# iqn_dio2 register map
Vendor: Texas Instruments
Registers are 32-bit, read-only, no defined reset value unless marked. A register's access mark holds for its fields unless they carry their own. Offsets are as the file gives them; [hi:lo] are bit positions; lines under a group give offsets from that group.

## IQN_DIO2 (part 2 of 2)
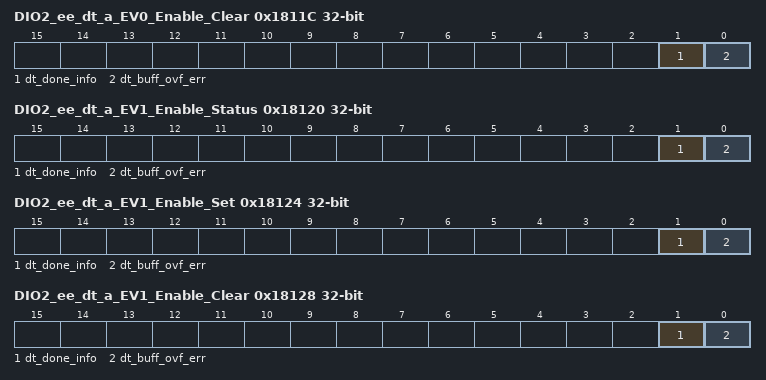
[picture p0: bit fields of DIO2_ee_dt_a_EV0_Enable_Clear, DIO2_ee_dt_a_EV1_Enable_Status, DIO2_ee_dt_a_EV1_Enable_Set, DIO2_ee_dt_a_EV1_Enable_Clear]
0x1811C DIO2_ee_dt_a_EV0_Enable_Clear wo — (1 of 1, stride 0)
  [1] dt_done_info — Clears the corresponding bit in the enable register when set. Write only, self-clears.
  [0] dt_buff_ovf_err — Clears the corresponding bit in the enable register when set. Write only, self-clears.
0x18120 DIO2_ee_dt_a_EV1_Enable_Status — (1 of 1, stride 0)
  [1] dt_done_info — When set allows the corresponding bit in the raw_status register to generate the intr1_sts interrupt. Read only.
  [0] dt_buff_ovf_err — When set allows the corresponding bit in the raw_status register to generate the intr1_sts interrupt. Read only.
0x18124 DIO2_ee_dt_a_EV1_Enable_Set wo — (1 of 1, stride 0)
  [1] dt_done_info — Sets the corresponding bit in the intr1_status register when set. Write only, self-clears.
  [0] dt_buff_ovf_err — Sets the corresponding bit in the intr1_status register when set. Write only, self-clears.
0x18128 DIO2_ee_dt_a_EV1_Enable_Clear wo — (1 of 1, stride 0)
  [1] dt_done_info — Clears the corresponding bit in the intr1_status register when set. Write only, self-clears.
  [0] dt_buff_ovf_err — Clears the corresponding bit in the intr1_status register when set. Write only, self-clears.
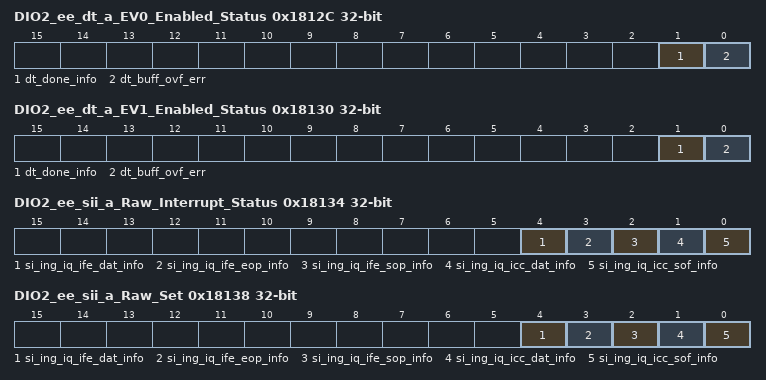
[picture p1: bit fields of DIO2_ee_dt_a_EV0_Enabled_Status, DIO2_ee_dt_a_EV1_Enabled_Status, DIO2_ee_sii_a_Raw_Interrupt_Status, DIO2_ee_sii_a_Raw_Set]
0x1812C DIO2_ee_dt_a_EV0_Enabled_Status — (1 of 1, stride 0)
  [1] dt_done_info — AND-ed raw_status bits with the corresponding bit in the enable_status register. Read only.
  [0] dt_buff_ovf_err — AND-ed raw_status bits with the corresponding bit in the enable_status register. Read only.
0x18130 DIO2_ee_dt_a_EV1_Enabled_Status — (1 of 1, stride 0)
  [1] dt_done_info — AND-ed raw_status bits with the corresponding bit in the intr1_status register. Read only.
  [0] dt_buff_ovf_err — AND-ed raw_status bits with the corresponding bit in the intr1_status register. Read only.
0x18134 DIO2_ee_sii_a_Raw_Interrupt_Status — (1 of 1, stride 0)
  [4] si_ing_iq_ife_dat_info — DIO SI Ingress IQ IFE transmitted valid data phase
  [3] si_ing_iq_ife_eop_info — DIO SI Ingress IQ IFE transmitted EOP
  [2] si_ing_iq_ife_sop_info — DIO SI Ingress IQ IFE transmitted SOP
  [1] si_ing_iq_icc_dat_info — DIO SI Ingress IQ ICC data transfer received
  [0] si_ing_iq_icc_sof_info — DIO SI Ingress IQ ICC Start of Frame received
0x18138 DIO2_ee_sii_a_Raw_Set wo — (1 of 1, stride 0)
  [4] si_ing_iq_ife_dat_info — Sets the corresponding bit in the raw_status register when set. Write only, self-clears.
  [3] si_ing_iq_ife_eop_info — Sets the corresponding bit in the raw_status register when set. Write only, self-clears.
  [2] si_ing_iq_ife_sop_info — Sets the corresponding bit in the raw_status register when set. Write only, self-clears.
  [1] si_ing_iq_icc_dat_info — Sets the corresponding bit in the raw_status register when set. Write only, self-clears.
  [0] si_ing_iq_icc_sof_info — Sets the corresponding bit in the raw_status register when set. Write only, self-clears.
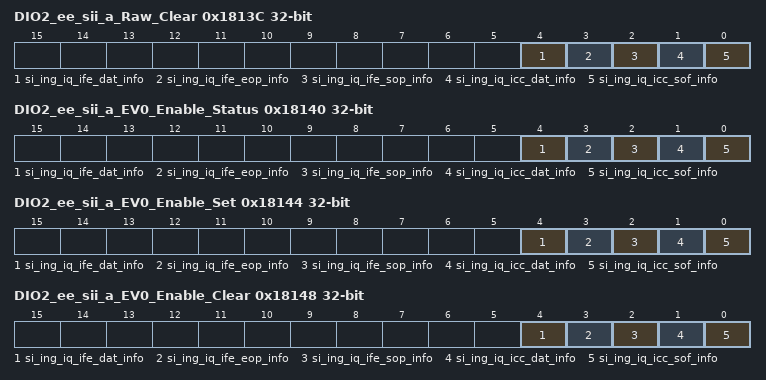
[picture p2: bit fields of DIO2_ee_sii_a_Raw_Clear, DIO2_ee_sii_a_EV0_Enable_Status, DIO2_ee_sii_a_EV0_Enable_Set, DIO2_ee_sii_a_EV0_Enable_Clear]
0x1813C DIO2_ee_sii_a_Raw_Clear wo — (1 of 1, stride 0)
  [4] si_ing_iq_ife_dat_info — Clears the corresponding bit in the raw_status register when set. Write only, self-clears.
  [3] si_ing_iq_ife_eop_info — Clears the corresponding bit in the raw_status register when set. Write only, self-clears.
  [2] si_ing_iq_ife_sop_info — Clears the corresponding bit in the raw_status register when set. Write only, self-clears.
  [1] si_ing_iq_icc_dat_info — Clears the corresponding bit in the raw_status register when set. Write only, self-clears.
  [0] si_ing_iq_icc_sof_info — Clears the corresponding bit in the raw_status register when set. Write only, self-clears.
0x18140 DIO2_ee_sii_a_EV0_Enable_Status — (1 of 1, stride 0)
  [4] si_ing_iq_ife_dat_info — When set allows the corresponding bit in the raw_status register to generate the intr_sts interrupt. Read only.
  [3] si_ing_iq_ife_eop_info — When set allows the corresponding bit in the raw_status register to generate the intr_sts interrupt. Read only.
  [2] si_ing_iq_ife_sop_info — When set allows the corresponding bit in the raw_status register to generate the intr_sts interrupt. Read only.
  [1] si_ing_iq_icc_dat_info — When set allows the corresponding bit in the raw_status register to generate the intr_sts interrupt. Read only.
  [0] si_ing_iq_icc_sof_info — When set allows the corresponding bit in the raw_status register to generate the intr_sts interrupt. Read only.
0x18144 DIO2_ee_sii_a_EV0_Enable_Set wo — (1 of 1, stride 0)
  [4] si_ing_iq_ife_dat_info — Sets the corresponding bit in the enable register when set. Write only, self-clears.
  [3] si_ing_iq_ife_eop_info — Sets the corresponding bit in the enable register when set. Write only, self-clears.
  [2] si_ing_iq_ife_sop_info — Sets the corresponding bit in the enable register when set. Write only, self-clears.
  [1] si_ing_iq_icc_dat_info — Sets the corresponding bit in the enable register when set. Write only, self-clears.
  [0] si_ing_iq_icc_sof_info — Sets the corresponding bit in the enable register when set. Write only, self-clears.
0x18148 DIO2_ee_sii_a_EV0_Enable_Clear wo — (1 of 1, stride 0)
  [4] si_ing_iq_ife_dat_info — Clears the corresponding bit in the enable register when set. Write only, self-clears.
  [3] si_ing_iq_ife_eop_info — Clears the corresponding bit in the enable register when set. Write only, self-clears.
  [2] si_ing_iq_ife_sop_info — Clears the corresponding bit in the enable register when set. Write only, self-clears.
  [1] si_ing_iq_icc_dat_info — Clears the corresponding bit in the enable register when set. Write only, self-clears.
  [0] si_ing_iq_icc_sof_info — Clears the corresponding bit in the enable register when set. Write only, self-clears.
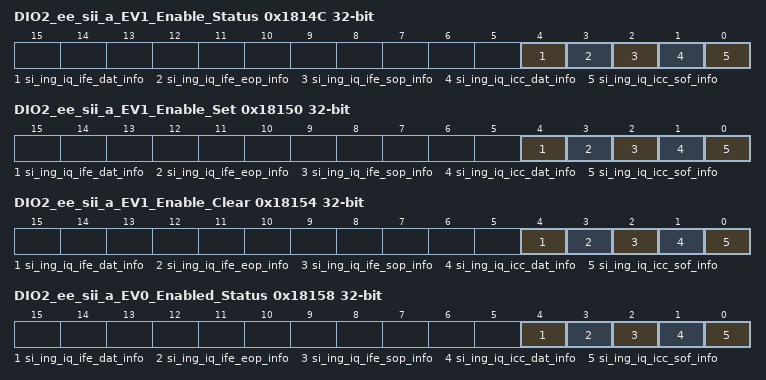
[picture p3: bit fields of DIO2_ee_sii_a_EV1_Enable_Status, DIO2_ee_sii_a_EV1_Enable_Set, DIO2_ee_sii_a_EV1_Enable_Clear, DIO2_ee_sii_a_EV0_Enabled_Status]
0x1814C DIO2_ee_sii_a_EV1_Enable_Status — (1 of 1, stride 0)
  [4] si_ing_iq_ife_dat_info — When set allows the corresponding bit in the raw_status register to generate the intr1_sts interrupt. Read only.
  [3] si_ing_iq_ife_eop_info — When set allows the corresponding bit in the raw_status register to generate the intr1_sts interrupt. Read only.
  [2] si_ing_iq_ife_sop_info — When set allows the corresponding bit in the raw_status register to generate the intr1_sts interrupt. Read only.
  [1] si_ing_iq_icc_dat_info — When set allows the corresponding bit in the raw_status register to generate the intr1_sts interrupt. Read only.
  [0] si_ing_iq_icc_sof_info — When set allows the corresponding bit in the raw_status register to generate the intr1_sts interrupt. Read only.
0x18150 DIO2_ee_sii_a_EV1_Enable_Set wo — (1 of 1, stride 0)
  [4] si_ing_iq_ife_dat_info — Sets the corresponding bit in the intr1_status register when set. Write only, self-clears.
  [3] si_ing_iq_ife_eop_info — Sets the corresponding bit in the intr1_status register when set. Write only, self-clears.
  [2] si_ing_iq_ife_sop_info — Sets the corresponding bit in the intr1_status register when set. Write only, self-clears.
  [1] si_ing_iq_icc_dat_info — Sets the corresponding bit in the intr1_status register when set. Write only, self-clears.
  [0] si_ing_iq_icc_sof_info — Sets the corresponding bit in the intr1_status register when set. Write only, self-clears.
0x18154 DIO2_ee_sii_a_EV1_Enable_Clear wo — (1 of 1, stride 0)
  [4] si_ing_iq_ife_dat_info — Clears the corresponding bit in the intr1_status register when set. Write only, self-clears.
  [3] si_ing_iq_ife_eop_info — Clears the corresponding bit in the intr1_status register when set. Write only, self-clears.
  [2] si_ing_iq_ife_sop_info — Clears the corresponding bit in the intr1_status register when set. Write only, self-clears.
  [1] si_ing_iq_icc_dat_info — Clears the corresponding bit in the intr1_status register when set. Write only, self-clears.
  [0] si_ing_iq_icc_sof_info — Clears the corresponding bit in the intr1_status register when set. Write only, self-clears.
0x18158 DIO2_ee_sii_a_EV0_Enabled_Status — (1 of 1, stride 0)
  [4] si_ing_iq_ife_dat_info — AND-ed raw_status bits with the corresponding bit in the enable_status register. Read only.
  [3] si_ing_iq_ife_eop_info — AND-ed raw_status bits with the corresponding bit in the enable_status register. Read only.
  [2] si_ing_iq_ife_sop_info — AND-ed raw_status bits with the corresponding bit in the enable_status register. Read only.
  [1] si_ing_iq_icc_dat_info — AND-ed raw_status bits with the corresponding bit in the enable_status register. Read only.
  [0] si_ing_iq_icc_sof_info — AND-ed raw_status bits with the corresponding bit in the enable_status register. Read only.
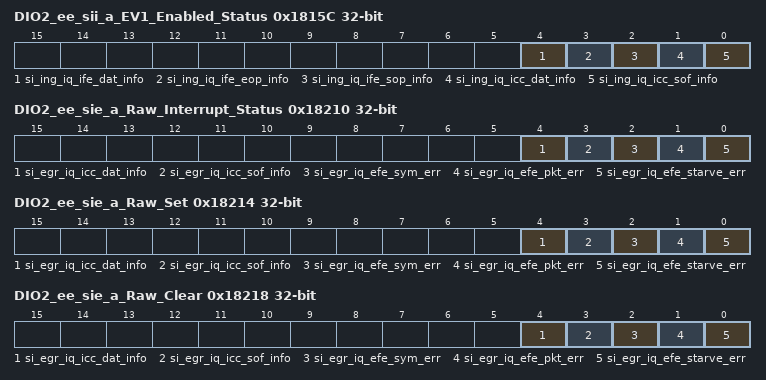
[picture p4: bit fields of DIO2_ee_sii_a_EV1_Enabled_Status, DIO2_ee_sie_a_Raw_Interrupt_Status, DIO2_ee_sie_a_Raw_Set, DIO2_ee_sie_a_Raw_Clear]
0x1815C DIO2_ee_sii_a_EV1_Enabled_Status — (1 of 1, stride 0)
  [4] si_ing_iq_ife_dat_info — AND-ed raw_status bits with the corresponding bit in the intr1_status register. Read only.
  [3] si_ing_iq_ife_eop_info — AND-ed raw_status bits with the corresponding bit in the intr1_status register. Read only.
  [2] si_ing_iq_ife_sop_info — AND-ed raw_status bits with the corresponding bit in the intr1_status register. Read only.
  [1] si_ing_iq_icc_dat_info — AND-ed raw_status bits with the corresponding bit in the intr1_status register. Read only.
  [0] si_ing_iq_icc_sof_info — AND-ed raw_status bits with the corresponding bit in the intr1_status register. Read only.
0x18160 DIO2_ee_sii_c_Raw_Interrupt_Status — (1 of 1, stride 0)
  [15:0] si_ing_iq_sof_err — DIO SI Ingress IQ per channel Start of Frame alignment error
0x18164 DIO2_ee_sii_c_Raw_Set wo — (1 of 1, stride 0)
  [15:0] si_ing_iq_sof_err — Sets the corresponding bit in the raw_status register when set. Write only, self-clears.
0x18168 DIO2_ee_sii_c_Raw_Clear wo — (1 of 1, stride 0)
  [15:0] si_ing_iq_sof_err — Clears the corresponding bit in the raw_status register when set. Write only, self-clears.
0x1816C DIO2_ee_sii_c_EV0_Enable_Status — (1 of 1, stride 0)
  [15:0] si_ing_iq_sof_err — When set allows the corresponding bit in the raw_status register to generate the intr_sts interrupt. Read only.
0x18170 DIO2_ee_sii_c_EV0_Enable_Set wo — (1 of 1, stride 0)
  [15:0] si_ing_iq_sof_err — Sets the corresponding bit in the enable register when set. Write only, self-clears.
0x18174 DIO2_ee_sii_c_EV0_Enable_Clear wo — (1 of 1, stride 0)
  [15:0] si_ing_iq_sof_err — Clears the corresponding bit in the enable register when set. Write only, self-clears.
0x18178 DIO2_ee_sii_c_EV1_Enable_Status — (1 of 1, stride 0)
  [15:0] si_ing_iq_sof_err — When set allows the corresponding bit in the raw_status register to generate the intr1_sts interrupt. Read only.
0x1817C DIO2_ee_sii_c_EV1_Enable_Set wo — (1 of 1, stride 0)
  [15:0] si_ing_iq_sof_err — Sets the corresponding bit in the intr1_status register when set. Write only, self-clears.
0x18180 DIO2_ee_sii_c_EV1_Enable_Clear wo — (1 of 1, stride 0)
  [15:0] si_ing_iq_sof_err — Clears the corresponding bit in the intr1_status register when set. Write only, self-clears.
0x18184 DIO2_ee_sii_c_EV0_Enabled_Status — (1 of 1, stride 0)
  [15:0] si_ing_iq_sof_err — AND-ed raw_status bits with the corresponding bit in the enable_status register. Read only.
0x18188 DIO2_ee_sii_c_EV1_Enabled_Status — (1 of 1, stride 0)
  [15:0] si_ing_iq_sof_err — AND-ed raw_status bits with the corresponding bit in the intr1_status register. Read only.
0x18210 DIO2_ee_sie_a_Raw_Interrupt_Status — (1 of 1, stride 0)
  [4] si_egr_iq_icc_dat_info — DIO SI Egress IQ transmitted data to ICC
  [3] si_egr_iq_icc_sof_info — DIO SI Egress IQ transmitted Start of Frame to ICC
  [2] si_egr_iq_efe_sym_err — DIO SI Egress IQ EFE symbol number error. (Packet boundary errors due to a missing, early, or late SOP disable the reporting of any symbol errors since the symbol number is only valid for SOPs)
  [1] si_egr_iq_efe_pkt_err — DIO SI Egress IQ EFE packet boundary error
  [0] si_egr_iq_efe_starve_err — DIO SI Egress IQ EFE data starvation error
0x18214 DIO2_ee_sie_a_Raw_Set wo — (1 of 1, stride 0)
  [4] si_egr_iq_icc_dat_info — Sets the corresponding bit in the raw_status register when set. Write only, self-clears.
  [3] si_egr_iq_icc_sof_info — Sets the corresponding bit in the raw_status register when set. Write only, self-clears.
  [2] si_egr_iq_efe_sym_err — Sets the corresponding bit in the raw_status register when set. Write only, self-clears.
  [1] si_egr_iq_efe_pkt_err — Sets the corresponding bit in the raw_status register when set. Write only, self-clears.
  [0] si_egr_iq_efe_starve_err — Sets the corresponding bit in the raw_status register when set. Write only, self-clears.
0x18218 DIO2_ee_sie_a_Raw_Clear wo — (1 of 1, stride 0)
  [4] si_egr_iq_icc_dat_info — Clears the corresponding bit in the raw_status register when set. Write only, self-clears.
  [3] si_egr_iq_icc_sof_info — Clears the corresponding bit in the raw_status register when set. Write only, self-clears.
  [2] si_egr_iq_efe_sym_err — Clears the corresponding bit in the raw_status register when set. Write only, self-clears.
  [1] si_egr_iq_efe_pkt_err — Clears the corresponding bit in the raw_status register when set. Write only, self-clears.
  [0] si_egr_iq_efe_starve_err — Clears the corresponding bit in the raw_status register when set. Write only, self-clears.
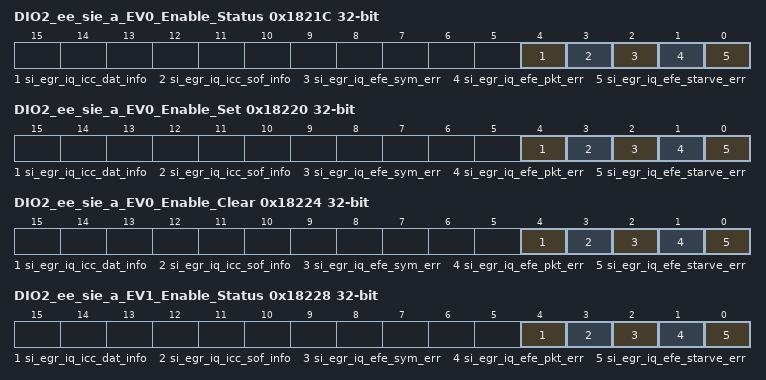
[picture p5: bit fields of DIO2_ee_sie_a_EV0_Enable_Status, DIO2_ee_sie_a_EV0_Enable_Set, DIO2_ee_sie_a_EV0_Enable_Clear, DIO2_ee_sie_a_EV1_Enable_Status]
0x1821C DIO2_ee_sie_a_EV0_Enable_Status — (1 of 1, stride 0)
  [4] si_egr_iq_icc_dat_info — When set allows the corresponding bit in the raw_status register to generate the intr_sts interrupt. Read only.
  [3] si_egr_iq_icc_sof_info — When set allows the corresponding bit in the raw_status register to generate the intr_sts interrupt. Read only.
  [2] si_egr_iq_efe_sym_err — When set allows the corresponding bit in the raw_status register to generate the intr_sts interrupt. Read only.
  [1] si_egr_iq_efe_pkt_err — When set allows the corresponding bit in the raw_status register to generate the intr_sts interrupt. Read only.
  [0] si_egr_iq_efe_starve_err — When set allows the corresponding bit in the raw_status register to generate the intr_sts interrupt. Read only.
0x18220 DIO2_ee_sie_a_EV0_Enable_Set wo — (1 of 1, stride 0)
  [4] si_egr_iq_icc_dat_info — Sets the corresponding bit in the enable register when set. Write only, self-clears.
  [3] si_egr_iq_icc_sof_info — Sets the corresponding bit in the enable register when set. Write only, self-clears.
  [2] si_egr_iq_efe_sym_err — Sets the corresponding bit in the enable register when set. Write only, self-clears.
  [1] si_egr_iq_efe_pkt_err — Sets the corresponding bit in the enable register when set. Write only, self-clears.
  [0] si_egr_iq_efe_starve_err — Sets the corresponding bit in the enable register when set. Write only, self-clears.
0x18224 DIO2_ee_sie_a_EV0_Enable_Clear wo — (1 of 1, stride 0)
  [4] si_egr_iq_icc_dat_info — Clears the corresponding bit in the enable register when set. Write only, self-clears.
  [3] si_egr_iq_icc_sof_info — Clears the corresponding bit in the enable register when set. Write only, self-clears.
  [2] si_egr_iq_efe_sym_err — Clears the corresponding bit in the enable register when set. Write only, self-clears.
  [1] si_egr_iq_efe_pkt_err — Clears the corresponding bit in the enable register when set. Write only, self-clears.
  [0] si_egr_iq_efe_starve_err — Clears the corresponding bit in the enable register when set. Write only, self-clears.
0x18228 DIO2_ee_sie_a_EV1_Enable_Status — (1 of 1, stride 0)
  [4] si_egr_iq_icc_dat_info — When set allows the corresponding bit in the raw_status register to generate the intr1_sts interrupt. Read only.
  [3] si_egr_iq_icc_sof_info — When set allows the corresponding bit in the raw_status register to generate the intr1_sts interrupt. Read only.
  [2] si_egr_iq_efe_sym_err — When set allows the corresponding bit in the raw_status register to generate the intr1_sts interrupt. Read only.
  [1] si_egr_iq_efe_pkt_err — When set allows the corresponding bit in the raw_status register to generate the intr1_sts interrupt. Read only.
  [0] si_egr_iq_efe_starve_err — When set allows the corresponding bit in the raw_status register to generate the intr1_sts interrupt. Read only.
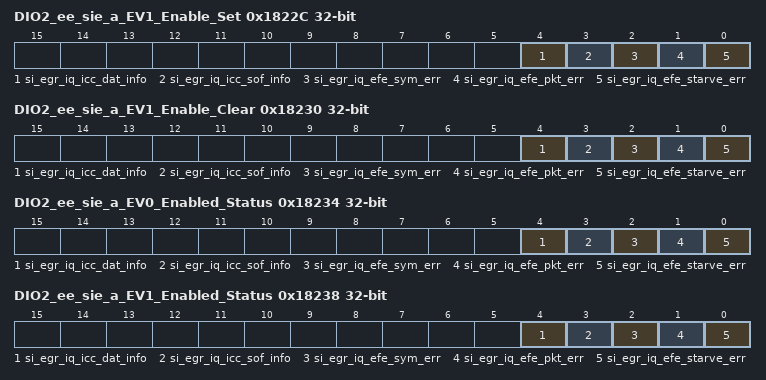
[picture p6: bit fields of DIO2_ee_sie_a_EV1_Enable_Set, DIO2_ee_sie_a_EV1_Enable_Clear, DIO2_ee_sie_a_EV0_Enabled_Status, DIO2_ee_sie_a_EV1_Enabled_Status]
0x1822C DIO2_ee_sie_a_EV1_Enable_Set wo — (1 of 1, stride 0)
  [4] si_egr_iq_icc_dat_info — Sets the corresponding bit in the intr1_status register when set. Write only, self-clears.
  [3] si_egr_iq_icc_sof_info — Sets the corresponding bit in the intr1_status register when set. Write only, self-clears.
  [2] si_egr_iq_efe_sym_err — Sets the corresponding bit in the intr1_status register when set. Write only, self-clears.
  [1] si_egr_iq_efe_pkt_err — Sets the corresponding bit in the intr1_status register when set. Write only, self-clears.
  [0] si_egr_iq_efe_starve_err — Sets the corresponding bit in the intr1_status register when set. Write only, self-clears.
0x18230 DIO2_ee_sie_a_EV1_Enable_Clear wo — (1 of 1, stride 0)
  [4] si_egr_iq_icc_dat_info — Clears the corresponding bit in the intr1_status register when set. Write only, self-clears.
  [3] si_egr_iq_icc_sof_info — Clears the corresponding bit in the intr1_status register when set. Write only, self-clears.
  [2] si_egr_iq_efe_sym_err — Clears the corresponding bit in the intr1_status register when set. Write only, self-clears.
  [1] si_egr_iq_efe_pkt_err — Clears the corresponding bit in the intr1_status register when set. Write only, self-clears.
  [0] si_egr_iq_efe_starve_err — Clears the corresponding bit in the intr1_status register when set. Write only, self-clears.
0x18234 DIO2_ee_sie_a_EV0_Enabled_Status — (1 of 1, stride 0)
  [4] si_egr_iq_icc_dat_info — AND-ed raw_status bits with the corresponding bit in the enable_status register. Read only.
  [3] si_egr_iq_icc_sof_info — AND-ed raw_status bits with the corresponding bit in the enable_status register. Read only.
  [2] si_egr_iq_efe_sym_err — AND-ed raw_status bits with the corresponding bit in the enable_status register. Read only.
  [1] si_egr_iq_efe_pkt_err — AND-ed raw_status bits with the corresponding bit in the enable_status register. Read only.
  [0] si_egr_iq_efe_starve_err — AND-ed raw_status bits with the corresponding bit in the enable_status register. Read only.
0x18238 DIO2_ee_sie_a_EV1_Enabled_Status — (1 of 1, stride 0)
  [4] si_egr_iq_icc_dat_info — AND-ed raw_status bits with the corresponding bit in the intr1_status register. Read only.
  [3] si_egr_iq_icc_sof_info — AND-ed raw_status bits with the corresponding bit in the intr1_status register. Read only.
  [2] si_egr_iq_efe_sym_err — AND-ed raw_status bits with the corresponding bit in the intr1_status register. Read only.
  [1] si_egr_iq_efe_pkt_err — AND-ed raw_status bits with the corresponding bit in the intr1_status register. Read only.
  [0] si_egr_iq_efe_starve_err — AND-ed raw_status bits with the corresponding bit in the intr1_status register. Read only.
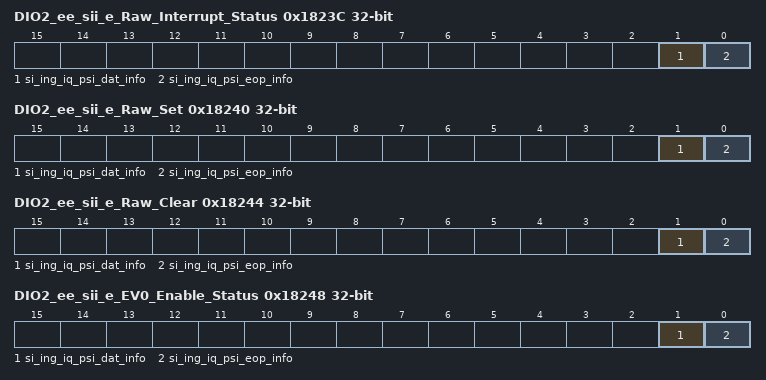
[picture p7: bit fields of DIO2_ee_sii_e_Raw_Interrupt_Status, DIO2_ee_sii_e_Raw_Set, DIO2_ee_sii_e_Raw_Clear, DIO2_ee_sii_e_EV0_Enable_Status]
0x1823C DIO2_ee_sii_e_Raw_Interrupt_Status — (1 of 1, stride 0)
  [1] si_ing_iq_psi_dat_info — DIO SI Ingress IQ data transmitted to PSI
  [0] si_ing_iq_psi_eop_info — DIO SI Ingress IQ EOP transmitted to PSI
0x18240 DIO2_ee_sii_e_Raw_Set wo — (1 of 1, stride 0)
  [1] si_ing_iq_psi_dat_info — Sets the corresponding bit in the raw_status register when set. Write only, self-clears.
  [0] si_ing_iq_psi_eop_info — Sets the corresponding bit in the raw_status register when set. Write only, self-clears.
0x18244 DIO2_ee_sii_e_Raw_Clear wo — (1 of 1, stride 0)
  [1] si_ing_iq_psi_dat_info — Clears the corresponding bit in the raw_status register when set. Write only, self-clears.
  [0] si_ing_iq_psi_eop_info — Clears the corresponding bit in the raw_status register when set. Write only, self-clears.
0x18248 DIO2_ee_sii_e_EV0_Enable_Status — (1 of 1, stride 0)
  [1] si_ing_iq_psi_dat_info — When set allows the corresponding bit in the raw_status register to generate the intr_sts interrupt. Read only.
  [0] si_ing_iq_psi_eop_info — When set allows the corresponding bit in the raw_status register to generate the intr_sts interrupt. Read only.
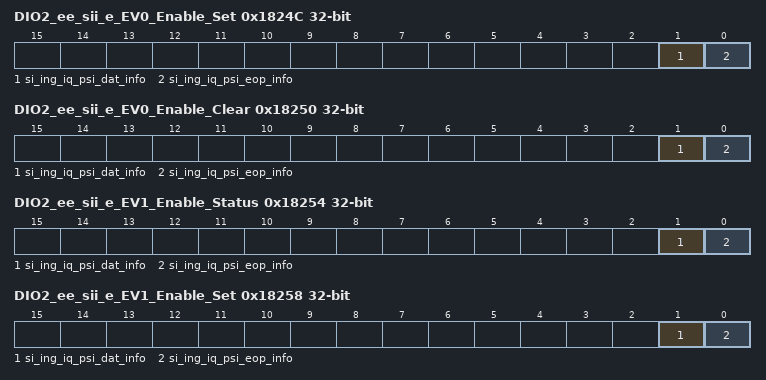
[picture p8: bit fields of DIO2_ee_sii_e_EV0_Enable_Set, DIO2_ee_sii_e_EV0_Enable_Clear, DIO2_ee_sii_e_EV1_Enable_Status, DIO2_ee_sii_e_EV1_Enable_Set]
0x1824C DIO2_ee_sii_e_EV0_Enable_Set wo — (1 of 1, stride 0)
  [1] si_ing_iq_psi_dat_info — Sets the corresponding bit in the enable register when set. Write only, self-clears.
  [0] si_ing_iq_psi_eop_info — Sets the corresponding bit in the enable register when set. Write only, self-clears.
0x18250 DIO2_ee_sii_e_EV0_Enable_Clear wo — (1 of 1, stride 0)
  [1] si_ing_iq_psi_dat_info — Clears the corresponding bit in the enable register when set. Write only, self-clears.
  [0] si_ing_iq_psi_eop_info — Clears the corresponding bit in the enable register when set. Write only, self-clears.
0x18254 DIO2_ee_sii_e_EV1_Enable_Status — (1 of 1, stride 0)
  [1] si_ing_iq_psi_dat_info — When set allows the corresponding bit in the raw_status register to generate the intr1_sts interrupt. Read only.
  [0] si_ing_iq_psi_eop_info — When set allows the corresponding bit in the raw_status register to generate the intr1_sts interrupt. Read only.
0x18258 DIO2_ee_sii_e_EV1_Enable_Set wo — (1 of 1, stride 0)
  [1] si_ing_iq_psi_dat_info — Sets the corresponding bit in the intr1_status register when set. Write only, self-clears.
  [0] si_ing_iq_psi_eop_info — Sets the corresponding bit in the intr1_status register when set. Write only, self-clears.
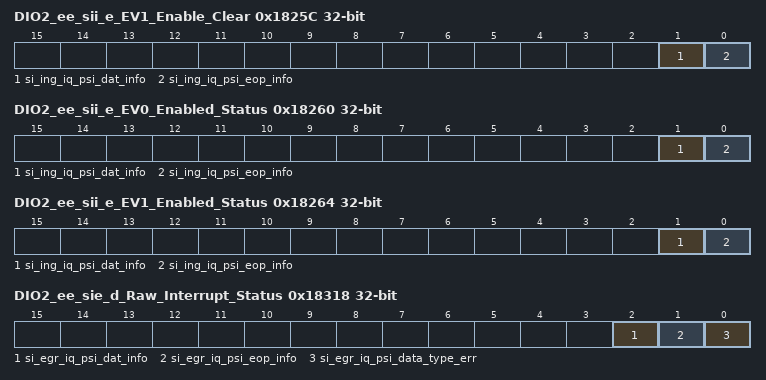
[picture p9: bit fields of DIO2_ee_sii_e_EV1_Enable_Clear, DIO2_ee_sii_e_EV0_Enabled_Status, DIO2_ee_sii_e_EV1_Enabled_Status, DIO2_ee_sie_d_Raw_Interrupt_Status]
0x1825C DIO2_ee_sii_e_EV1_Enable_Clear wo — (1 of 1, stride 0)
  [1] si_ing_iq_psi_dat_info — Clears the corresponding bit in the intr1_status register when set. Write only, self-clears.
  [0] si_ing_iq_psi_eop_info — Clears the corresponding bit in the intr1_status register when set. Write only, self-clears.
0x18260 DIO2_ee_sii_e_EV0_Enabled_Status — (1 of 1, stride 0)
  [1] si_ing_iq_psi_dat_info — AND-ed raw_status bits with the corresponding bit in the enable_status register. Read only.
  [0] si_ing_iq_psi_eop_info — AND-ed raw_status bits with the corresponding bit in the enable_status register. Read only.
0x18264 DIO2_ee_sii_e_EV1_Enabled_Status — (1 of 1, stride 0)
  [1] si_ing_iq_psi_dat_info — AND-ed raw_status bits with the corresponding bit in the intr1_status register. Read only.
  [0] si_ing_iq_psi_eop_info — AND-ed raw_status bits with the corresponding bit in the intr1_status register. Read only.
0x18268 DIO2_ee_sii_g_Raw_Interrupt_Status — (1 of 1, stride 0)
  [15:0] si_ing_iq_psi_sop_info — DIO SI Ingress IQ SOP transmitted to PSI
0x1826C DIO2_ee_sii_g_Raw_Set wo — (1 of 1, stride 0)
  [15:0] si_ing_iq_psi_sop_info — Sets the corresponding bit in the raw_status register when set. Write only, self-clears.
0x18270 DIO2_ee_sii_g_Raw_Clear wo — (1 of 1, stride 0)
  [15:0] si_ing_iq_psi_sop_info — Clears the corresponding bit in the raw_status register when set. Write only, self-clears.
0x18274 DIO2_ee_sii_g_EV0_Enable_Status — (1 of 1, stride 0)
  [15:0] si_ing_iq_psi_sop_info — When set allows the corresponding bit in the raw_status register to generate the intr_sts interrupt. Read only.
0x18278 DIO2_ee_sii_g_EV0_Enable_Set wo — (1 of 1, stride 0)
  [15:0] si_ing_iq_psi_sop_info — Sets the corresponding bit in the enable register when set. Write only, self-clears.
0x1827C DIO2_ee_sii_g_EV0_Enable_Clear wo — (1 of 1, stride 0)
  [15:0] si_ing_iq_psi_sop_info — Clears the corresponding bit in the enable register when set. Write only, self-clears.
0x18280 DIO2_ee_sii_g_EV1_Enable_Status — (1 of 1, stride 0)
  [15:0] si_ing_iq_psi_sop_info — When set allows the corresponding bit in the raw_status register to generate the intr1_sts interrupt. Read only.
0x18284 DIO2_ee_sii_g_EV1_Enable_Set wo — (1 of 1, stride 0)
  [15:0] si_ing_iq_psi_sop_info — Sets the corresponding bit in the intr1_status register when set. Write only, self-clears.
0x18288 DIO2_ee_sii_g_EV1_Enable_Clear wo — (1 of 1, stride 0)
  [15:0] si_ing_iq_psi_sop_info — Clears the corresponding bit in the intr1_status register when set. Write only, self-clears.
0x1828C DIO2_ee_sii_g_EV0_Enabled_Status — (1 of 1, stride 0)
  [15:0] si_ing_iq_psi_sop_info — AND-ed raw_status bits with the corresponding bit in the enable_status register. Read only.
0x18290 DIO2_ee_sii_g_EV1_Enabled_Status — (1 of 1, stride 0)
  [15:0] si_ing_iq_psi_sop_info — AND-ed raw_status bits with the corresponding bit in the intr1_status register. Read only.
0x18318 DIO2_ee_sie_d_Raw_Interrupt_Status — (1 of 1, stride 0)
  [2] si_egr_iq_psi_dat_info — DIO SI Egress IQ valid data received from PSI
  [1] si_egr_iq_psi_eop_info — DIO SI Egress IQ EOP received from PSI
  [0] si_egr_iq_psi_data_type_err — DIO SI Egress IQ PSI data type error
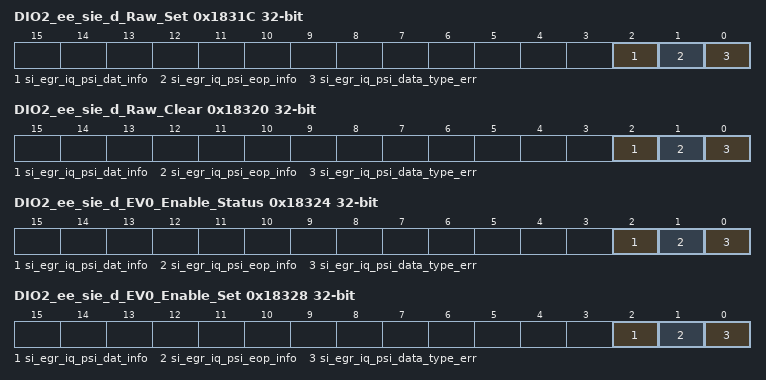
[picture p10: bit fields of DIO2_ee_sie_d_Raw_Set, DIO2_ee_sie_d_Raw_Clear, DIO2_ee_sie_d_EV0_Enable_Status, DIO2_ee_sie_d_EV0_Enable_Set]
0x1831C DIO2_ee_sie_d_Raw_Set wo — (1 of 1, stride 0)
  [2] si_egr_iq_psi_dat_info — Sets the corresponding bit in the raw_status register when set. Write only, self-clears.
  [1] si_egr_iq_psi_eop_info — Sets the corresponding bit in the raw_status register when set. Write only, self-clears.
  [0] si_egr_iq_psi_data_type_err — Sets the corresponding bit in the raw_status register when set. Write only, self-clears.
0x18320 DIO2_ee_sie_d_Raw_Clear wo — (1 of 1, stride 0)
  [2] si_egr_iq_psi_dat_info — Clears the corresponding bit in the raw_status register when set. Write only, self-clears.
  [1] si_egr_iq_psi_eop_info — Clears the corresponding bit in the raw_status register when set. Write only, self-clears.
  [0] si_egr_iq_psi_data_type_err — Clears the corresponding bit in the raw_status register when set. Write only, self-clears.
0x18324 DIO2_ee_sie_d_EV0_Enable_Status — (1 of 1, stride 0)
  [2] si_egr_iq_psi_dat_info — When set allows the corresponding bit in the raw_status register to generate the intr_sts interrupt. Read only.
  [1] si_egr_iq_psi_eop_info — When set allows the corresponding bit in the raw_status register to generate the intr_sts interrupt. Read only.
  [0] si_egr_iq_psi_data_type_err — When set allows the corresponding bit in the raw_status register to generate the intr_sts interrupt. Read only.
0x18328 DIO2_ee_sie_d_EV0_Enable_Set wo — (1 of 1, stride 0)
  [2] si_egr_iq_psi_dat_info — Sets the corresponding bit in the enable register when set. Write only, self-clears.
  [1] si_egr_iq_psi_eop_info — Sets the corresponding bit in the enable register when set. Write only, self-clears.
  [0] si_egr_iq_psi_data_type_err — Sets the corresponding bit in the enable register when set. Write only, self-clears.
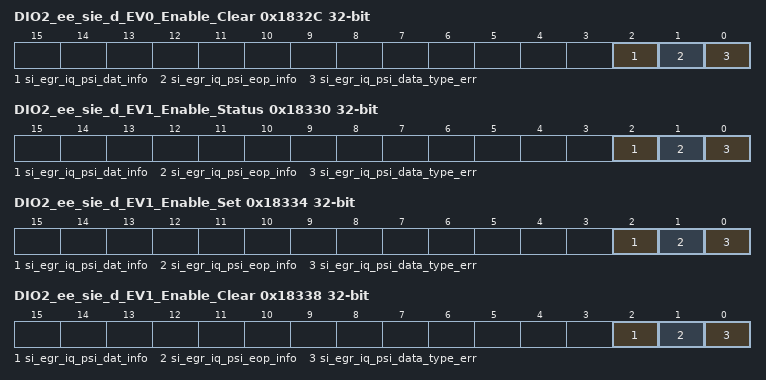
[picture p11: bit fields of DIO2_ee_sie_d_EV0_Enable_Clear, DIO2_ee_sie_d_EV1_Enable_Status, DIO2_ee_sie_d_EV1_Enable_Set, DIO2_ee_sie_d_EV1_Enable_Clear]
0x1832C DIO2_ee_sie_d_EV0_Enable_Clear wo — (1 of 1, stride 0)
  [2] si_egr_iq_psi_dat_info — Clears the corresponding bit in the enable register when set. Write only, self-clears.
  [1] si_egr_iq_psi_eop_info — Clears the corresponding bit in the enable register when set. Write only, self-clears.
  [0] si_egr_iq_psi_data_type_err — Clears the corresponding bit in the enable register when set. Write only, self-clears.
0x18330 DIO2_ee_sie_d_EV1_Enable_Status — (1 of 1, stride 0)
  [2] si_egr_iq_psi_dat_info — When set allows the corresponding bit in the raw_status register to generate the intr1_sts interrupt. Read only.
  [1] si_egr_iq_psi_eop_info — When set allows the corresponding bit in the raw_status register to generate the intr1_sts interrupt. Read only.
  [0] si_egr_iq_psi_data_type_err — When set allows the corresponding bit in the raw_status register to generate the intr1_sts interrupt. Read only.
0x18334 DIO2_ee_sie_d_EV1_Enable_Set wo — (1 of 1, stride 0)
  [2] si_egr_iq_psi_dat_info — Sets the corresponding bit in the intr1_status register when set. Write only, self-clears.
  [1] si_egr_iq_psi_eop_info — Sets the corresponding bit in the intr1_status register when set. Write only, self-clears.
  [0] si_egr_iq_psi_data_type_err — Sets the corresponding bit in the intr1_status register when set. Write only, self-clears.
0x18338 DIO2_ee_sie_d_EV1_Enable_Clear wo — (1 of 1, stride 0)
  [2] si_egr_iq_psi_dat_info — Clears the corresponding bit in the intr1_status register when set. Write only, self-clears.
  [1] si_egr_iq_psi_eop_info — Clears the corresponding bit in the intr1_status register when set. Write only, self-clears.
  [0] si_egr_iq_psi_data_type_err — Clears the corresponding bit in the intr1_status register when set. Write only, self-clears.
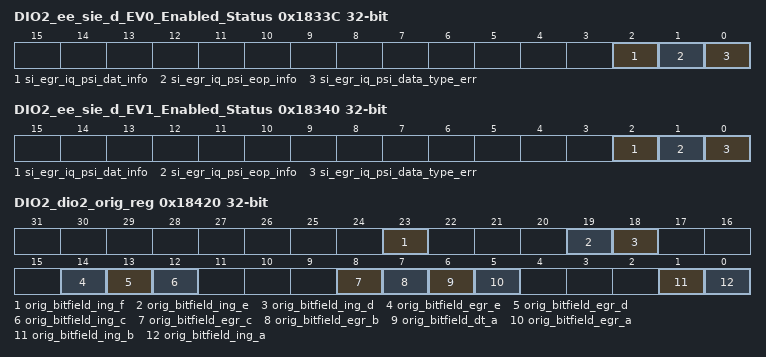
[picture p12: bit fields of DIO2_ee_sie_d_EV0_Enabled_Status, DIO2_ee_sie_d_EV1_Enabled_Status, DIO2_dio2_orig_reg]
0x1833C DIO2_ee_sie_d_EV0_Enabled_Status — (1 of 1, stride 0)
  [2] si_egr_iq_psi_dat_info — AND-ed raw_status bits with the corresponding bit in the enable_status register. Read only.
  [1] si_egr_iq_psi_eop_info — AND-ed raw_status bits with the corresponding bit in the enable_status register. Read only.
  [0] si_egr_iq_psi_data_type_err — AND-ed raw_status bits with the corresponding bit in the enable_status register. Read only.
0x18340 DIO2_ee_sie_d_EV1_Enabled_Status — (1 of 1, stride 0)
  [2] si_egr_iq_psi_dat_info — AND-ed raw_status bits with the corresponding bit in the intr1_status register. Read only.
  [1] si_egr_iq_psi_eop_info — AND-ed raw_status bits with the corresponding bit in the intr1_status register. Read only.
  [0] si_egr_iq_psi_data_type_err — AND-ed raw_status bits with the corresponding bit in the intr1_status register. Read only.
0x18344 DIO2_ee_sie_e_Raw_Interrupt_Status access not given — (1 of 1, stride 0)
0x18348 DIO2_ee_sie_e_Raw_Set access not given — (1 of 1, stride 0)
0x1834C DIO2_ee_sie_e_Raw_Clear access not given — (1 of 1, stride 0)
0x18350 DIO2_ee_sie_e_EV0_Enable_Status access not given — (1 of 1, stride 0)
0x18354 DIO2_ee_sie_e_EV0_Enable_Set access not given — (1 of 1, stride 0)
0x18358 DIO2_ee_sie_e_EV0_Enable_Clear access not given — (1 of 1, stride 0)
0x1835C DIO2_ee_sie_e_EV1_Enable_Status access not given — (1 of 1, stride 0)
0x18360 DIO2_ee_sie_e_EV1_Enable_Set access not given — (1 of 1, stride 0)
0x18364 DIO2_ee_sie_e_EV1_Enable_Clear access not given — (1 of 1, stride 0)
0x18368 DIO2_ee_sie_e_EV0_Enabled_Status access not given — (1 of 1, stride 0)
0x1836C DIO2_ee_sie_e_EV1_Enabled_Status access not given — (1 of 1, stride 0)
0x18370 DIO2_ee_sie_f_Raw_Interrupt_Status — (1 of 1, stride 0)
  [15:0] si_egr_iq_psi_sop_info — DIO SI Ingress IQ per channel SOP received from PSI
0x18374 DIO2_ee_sie_f_Raw_Set wo — (1 of 1, stride 0)
  [15:0] si_egr_iq_psi_sop_info — Sets the corresponding bit in the raw_status register when set. Write only, self-clears.
0x18378 DIO2_ee_sie_f_Raw_Clear wo — (1 of 1, stride 0)
  [15:0] si_egr_iq_psi_sop_info — Clears the corresponding bit in the raw_status register when set. Write only, self-clears.
0x1837C DIO2_ee_sie_f_EV0_Enable_Status — (1 of 1, stride 0)
  [15:0] si_egr_iq_psi_sop_info — When set allows the corresponding bit in the raw_status register to generate the intr_sts interrupt. Read only.
0x18380 DIO2_ee_sie_f_EV0_Enable_Set wo — (1 of 1, stride 0)
  [15:0] si_egr_iq_psi_sop_info — Sets the corresponding bit in the enable register when set. Write only, self-clears.
0x18384 DIO2_ee_sie_f_EV0_Enable_Clear wo — (1 of 1, stride 0)
  [15:0] si_egr_iq_psi_sop_info — Clears the corresponding bit in the enable register when set. Write only, self-clears.
0x18388 DIO2_ee_sie_f_EV1_Enable_Status — (1 of 1, stride 0)
  [15:0] si_egr_iq_psi_sop_info — When set allows the corresponding bit in the raw_status register to generate the intr1_sts interrupt. Read only.
0x1838C DIO2_ee_sie_f_EV1_Enable_Set wo — (1 of 1, stride 0)
  [15:0] si_egr_iq_psi_sop_info — Sets the corresponding bit in the intr1_status register when set. Write only, self-clears.
0x18390 DIO2_ee_sie_f_EV1_Enable_Clear wo — (1 of 1, stride 0)
  [15:0] si_egr_iq_psi_sop_info — Clears the corresponding bit in the intr1_status register when set. Write only, self-clears.
0x18394 DIO2_ee_sie_f_EV0_Enabled_Status — (1 of 1, stride 0)
  [15:0] si_egr_iq_psi_sop_info — AND-ed raw_status bits with the corresponding bit in the enable_status register. Read only.
0x18398 DIO2_ee_sie_f_EV1_Enabled_Status — (1 of 1, stride 0)
  [15:0] si_egr_iq_psi_sop_info — AND-ed raw_status bits with the corresponding bit in the intr1_status register. Read only.
0x18420 DIO2_dio2_orig_reg — (1 of 1, stride 0)
  [23] orig_bitfield_ing_f — DIO ee_ing_f group of DIO Ingress (SI egress ee_sie_f) registers
  [19] orig_bitfield_ing_e — DIO ee_ing_e group of DIO Ingress (SI egress ee_sie_e) registers
  [18] orig_bitfield_ing_d — DIO ee_ing_d group of DIO Ingress (SI egress ee_sie_d) registers
  [14] orig_bitfield_egr_e — DIO ee_egr_e group of DIO Egress (SI ingress ee_sii_g) registers
  [13] orig_bitfield_egr_d — DIO ee_egr_d group of DIO Egress (SI ingress ee_sii_e) registers
  [12] orig_bitfield_ing_c — DIO ee_ing_c group of DIO Ingress (SI egress ee_sie_a) registers
  [8] orig_bitfield_egr_c — DIO ee_egr_c group of DIO Egress (SI ingress ee_sii_c) registers
  [7] orig_bitfield_egr_b — DIO ee_egr_b group of DIO Egress (SI ingress ee_sii_a) registers
  [6] orig_bitfield_dt_a — DIO ee_dt_a group of DIO Data Trace registers
  [5] orig_bitfield_egr_a — DIO ee_dma_egr_a group of DIO Egress core registers
  [1] orig_bitfield_ing_b — DIO ee_dma_ing_b group of DIO Ingress core registers
  [0] orig_bitfield_ing_a — DIO ee_dma_ing_a group of DIO Ingress core registers
